# SH30F2xx register map
Vendor: Sino Wealth Electronic Ltd.; Series: SH30Fxxx; File version: 1.0
CPU: CM0+ r0p1, little endian, no MPU, no FPU, 2 interrupt priority bits
Registers are 32-bit, read-write, reset 0x0 unless marked. A register's access mark holds for its fields unless they carry their own. Offsets are from the block's base; [hi:lo] are bit positions; {n}, {i} and the like mark numbered series; 'fields as' and 'values as' point back to an identical list.

## SYSCFG
Base 0x40040800
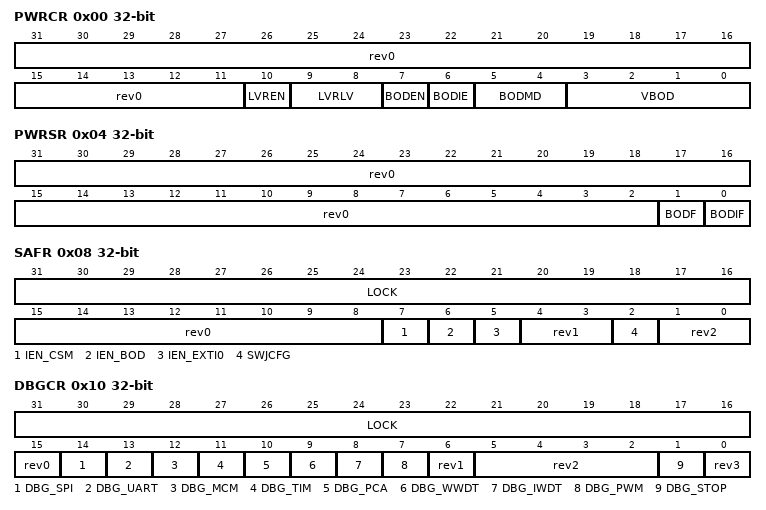
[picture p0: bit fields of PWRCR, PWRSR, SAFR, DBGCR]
0x00 PWRCR
  [31:11] rev0, [10] LVREN, [9:8] LVRLV, [7] BODEN, [6] BODIE, [5:4] BODMD, [3:0] VBOD
0x04 PWRSR
  [31:2] rev0, [1] BODF ro, [0] BODIF
0x08 SAFR
  [31:16] LOCK, [15:8] rev0, [7] IEN_CSM, [6] IEN_BOD, [5] IEN_EXTI0, [4:3] rev1, [2] SWJCFG, [1:0] rev2
0x10 DBGCR
  [31:16] LOCK, [15] rev0, [14] DBG_SPI, [13] DBG_UART, [12] DBG_MCM, [11] DBG_TIM, [10] DBG_PCA, [9] DBG_WWDT, [8] DBG_IWDT, [7] DBG_PWM, [6] rev1, [5:2] rev2, [1] DBG_STOP, [0] rev3
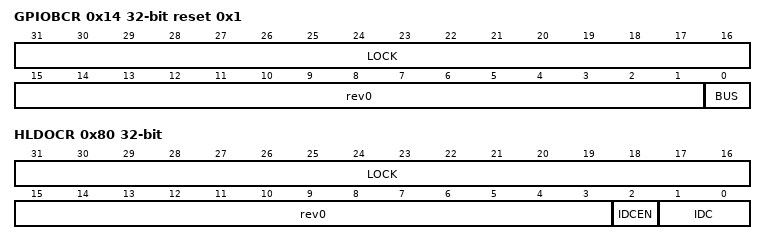
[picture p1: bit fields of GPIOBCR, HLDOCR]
0x14 GPIOBCR reset 0x1
  [31:16] LOCK, [15:1] rev0, [0] BUS
0x80 HLDOCR
  [31:16] LOCK, [15:3] rev0, [2] IDCEN, [1:0] IDC

## RCC
Base 0x40040C00
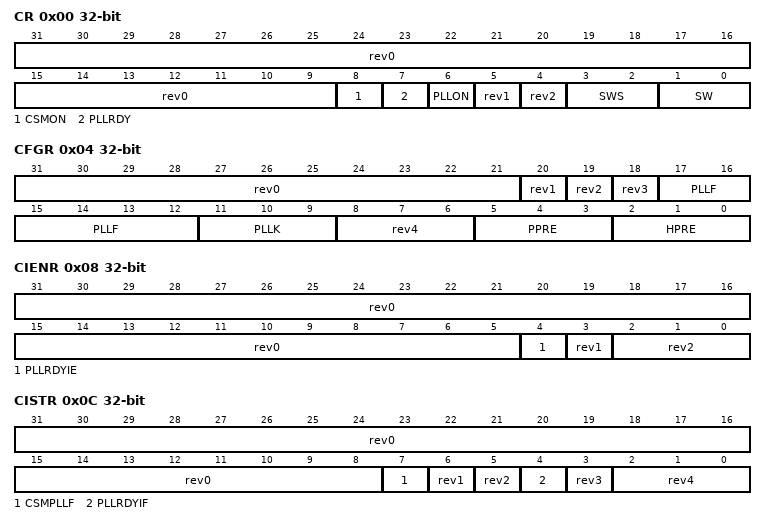
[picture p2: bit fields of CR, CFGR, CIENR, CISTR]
0x00 CR
  [31:9] rev0, [8] CSMON, [7] PLLRDY ro, [6] PLLON, [5] rev1 ro, [4] rev2, [3:2] SWS ro, [1:0] SW
0x04 CFGR
  [31:21] rev0, [20] rev1, [19] rev2, [18] rev3, [17:12] PLLF, [11:9] PLLK, [8:6] rev4, [5:3] PPRE, [2:0] HPRE
0x08 CIENR
  [31:5] rev0, [4] PLLRDYIE, [3] rev1, [2:0] rev2
0x0C CISTR ro
  [31:8] rev0 rw, [7] CSMPLLF, [6] rev1, [5] rev2 rw, [4] PLLRDYIF, [3] rev3, [2:0] rev4 rw
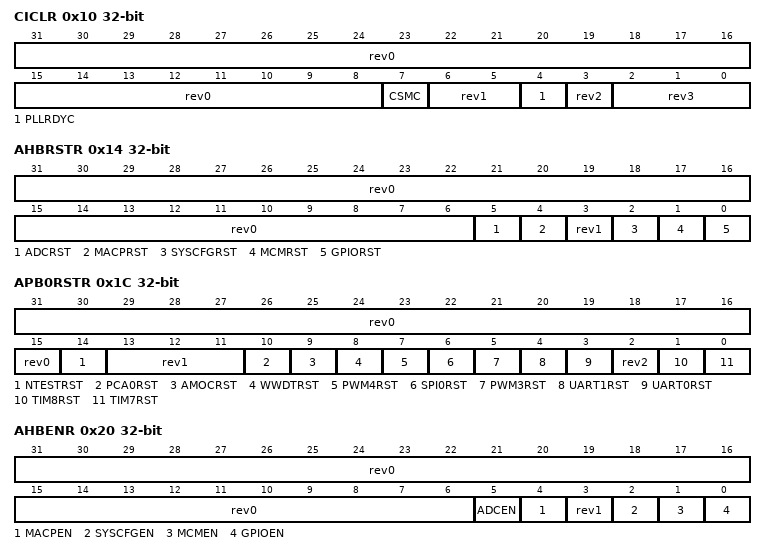
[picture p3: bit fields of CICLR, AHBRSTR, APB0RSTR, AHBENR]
0x10 CICLR
  [31:8] rev0, [7] CSMC, [6:5] rev1, [4] PLLRDYC, [3] rev2, [2:0] rev3
0x14 AHBRSTR
  [31:6] rev0, [5] ADCRST, [4] MACPRST, [3] rev1, [2] SYSCFGRST, [1] MCMRST, [0] GPIORST
0x1C APB0RSTR
  [31:15] rev0, [14] NTESTRST, [13:11] rev1, [10] PCA0RST, [9] AMOCRST, [8] WWDTRST, [7] PWM4RST, [6] SPI0RST, [5] PWM3RST, [4] UART1RST, [3] UART0RST, [2] rev2, [1] TIM8RST, [0] TIM7RST
0x20 AHBENR
  [31:6] rev0, [5] ADCEN, [4] MACPEN, [3] rev1, [2] SYSCFGEN, [1] MCMEN, [0] GPIOEN
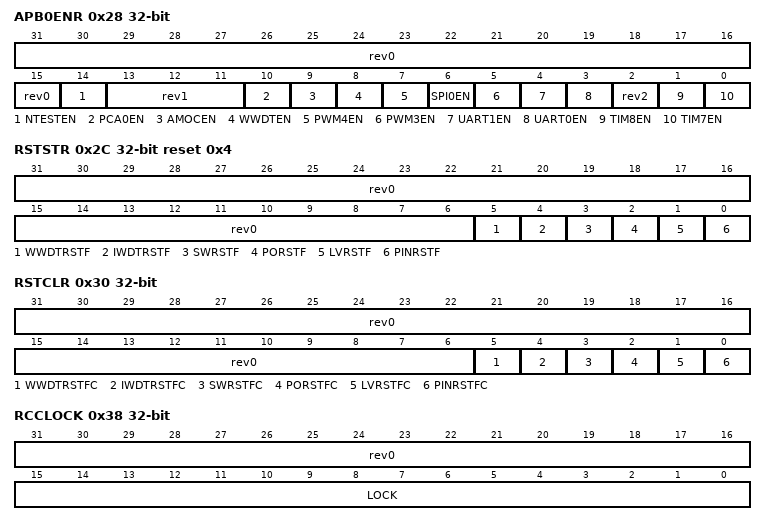
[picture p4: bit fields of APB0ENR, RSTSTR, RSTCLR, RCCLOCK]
0x28 APB0ENR
  [31:15] rev0, [14] NTESTEN, [13:11] rev1, [10] PCA0EN, [9] AMOCEN, [8] WWDTEN, [7] PWM4EN, [6] SPI0EN, [5] PWM3EN, [4] UART1EN, [3] UART0EN, [2] rev2, [1] TIM8EN, [0] TIM7EN
0x2C RSTSTR ro reset 0x4
  [31:6] rev0 rw, [5] WWDTRSTF, [4] IWDTRSTF, [3] SWRSTF, [2] PORSTF, [1] LVRSTF, [0] PINRSTF
0x30 RSTCLR
  [31:6] rev0, [5] WWDTRSTFC, [4] IWDTRSTFC, [3] SWRSTFC, [2] PORSTFC, [1] LVRSTFC, [0] PINRSTFC
0x38 RCCLOCK
  [31:16] rev0, [15:0] LOCK

## FLASH
Base 0x40041000
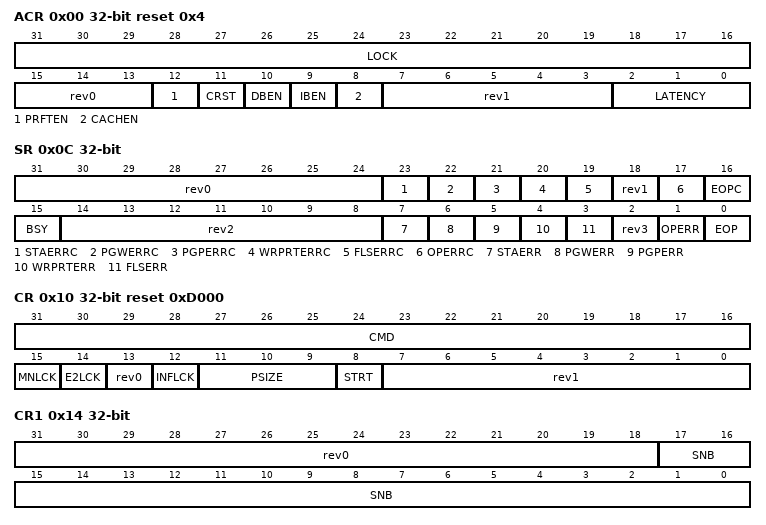
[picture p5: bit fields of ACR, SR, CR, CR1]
0x00 ACR reset 0x4
  [31:16] LOCK, [15:13] rev0, [12] PRFTEN, [11] CRST, [10] DBEN, [9] IBEN, [8] CACHEN, [7:3] rev1, [2:0] LATENCY
0x04 MKYR wo
0x08 E2KYR wo
0x0C SR
  [31:24] rev0, [23] STAERRC, [22] PGWERRC, [21] PGPERRC, [20] WRPRTERRC, [19] FLSERRC, [18] rev1, [17] OPERRC, [16] EOPC, [15] BSY ro, [14:8] rev2, [7] STAERR ro, [6] PGWERR ro, [5] PGPERR ro, [4] WRPRTERR ro, [3] FLSERR ro, [2] rev3, [1] OPERR ro, [0] EOP ro
0x10 CR reset 0xD000
  [31:16] CMD, [15] MNLCK, [14] E2LCK, [13] rev0, [12] INFLCK, [11:9] PSIZE, [8] STRT, [7:0] rev1
0x14 CR1
  [31:18] rev0, [17:0] SNB
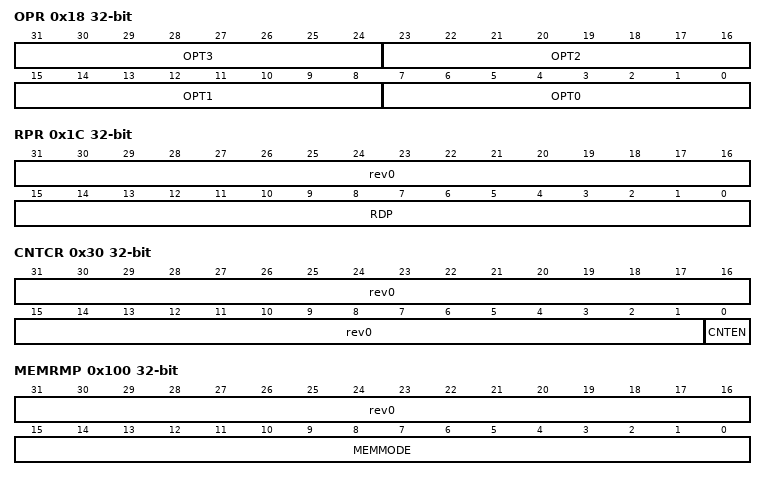
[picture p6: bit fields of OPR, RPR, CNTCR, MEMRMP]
0x18 OPR ro
  [8n+7:8n] OPT{n} (n=0..3)
0x1C RPR ro
  [31:16] rev0 rw, [15:0] RDP
0x20 WRPR ro
0x24 WRPR1 ro
0x28 CNTR
0x2C UPCNTR
0x30 CNTCR
  [31:1] rev0, [0] CNTEN
0x34 IKYR wo
{0x38+4i} DATA{i} (i=0..2)
0x100 MEMRMP
  [31:16] rev0, [15:0] MEMMODE
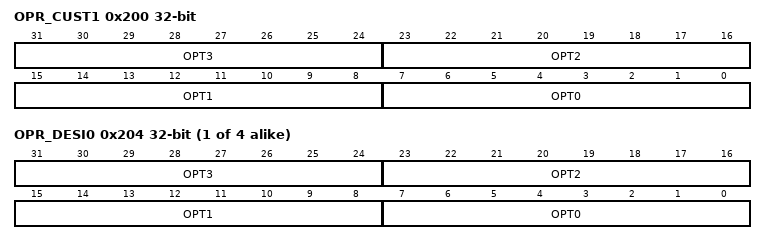
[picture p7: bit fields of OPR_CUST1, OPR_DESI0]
0x200 OPR_CUST1 ro
  [8n+7:8n] OPT{n} (n=0..3)
{0x204+4i} OPR_DESI{i} ro (i=0..3)
  [8n+7:8n] OPT{n} (n=0..3)

## MACP
Base 0x40041400
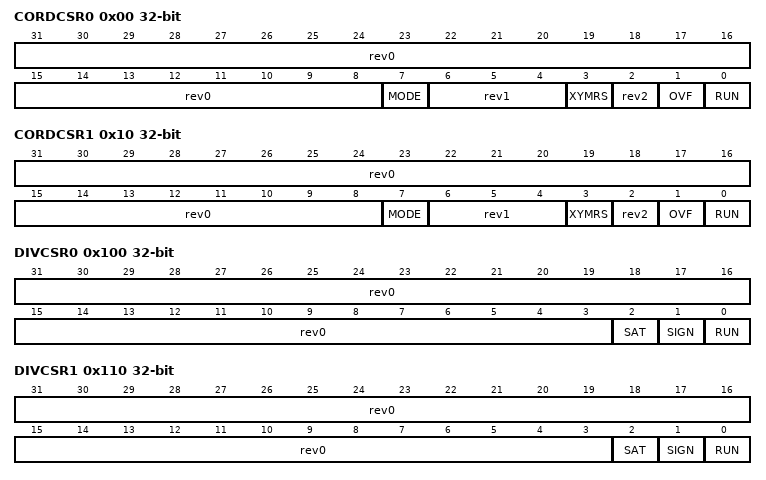
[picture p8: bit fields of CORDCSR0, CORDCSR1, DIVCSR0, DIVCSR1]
0x00 CORDCSR0
  [31:8] rev0, [7] MODE, [6:4] rev1, [3] XYMRS, [2] rev2, [1] OVF ro, [0] RUN
0x04 OPRDX0
0x08 OPRDY0
0x0C OPRDZ0
0x10 CORDCSR1
  fields as CORDCSR0
0x14 OPRDX1
0x18 OPRDY1
0x1C OPRDZ1
0x100 DIVCSR0
  [31:3] rev0, [2] SAT, [1] SIGN, [0] RUN
0x104 DIVDND0
0x108 DIVSOR0
0x10C DIVRLT0 ro
0x110 DIVCSR1
  [31:3] rev0, [2] SAT, [1] SIGN, [0] RUN
0x114 DIVDND1
0x118 DIVSOR1
0x11C DIVRLT1 ro

## ADC
Base 0x40041800
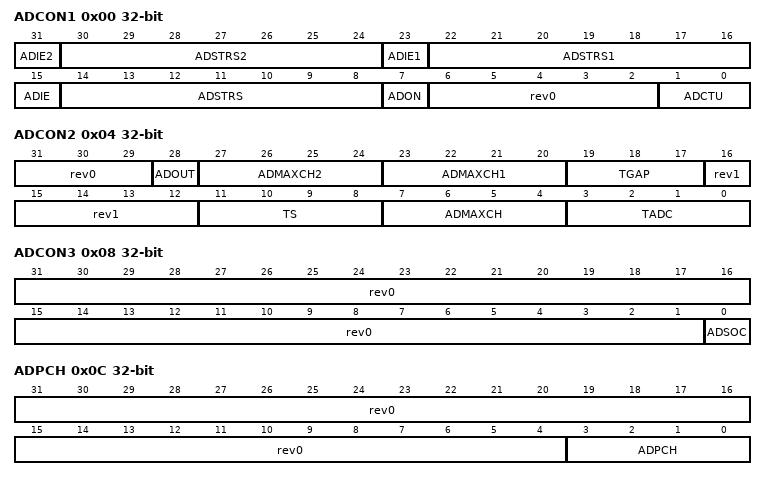
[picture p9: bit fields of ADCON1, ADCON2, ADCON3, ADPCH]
0x00 ADCON1
  [31] ADIE2, [30:24] ADSTRS2, [23] ADIE1, [22:16] ADSTRS1, [15] ADIE, [14:8] ADSTRS, [7] ADON, [6:2] rev0, [1:0] ADCTU
0x04 ADCON2
  [31:29] rev0, [28] ADOUT, [27:24] ADMAXCH2, [23:20] ADMAXCH1, [19:17] TGAP, [16:12] rev1, [11:8] TS, [7:4] ADMAXCH, [3:0] TADC
0x08 ADCON3
  [31:1] rev0, [0] ADSOC
0x0C ADPCH ro
  [31:4] rev0 rw, [3:0] ADPCH
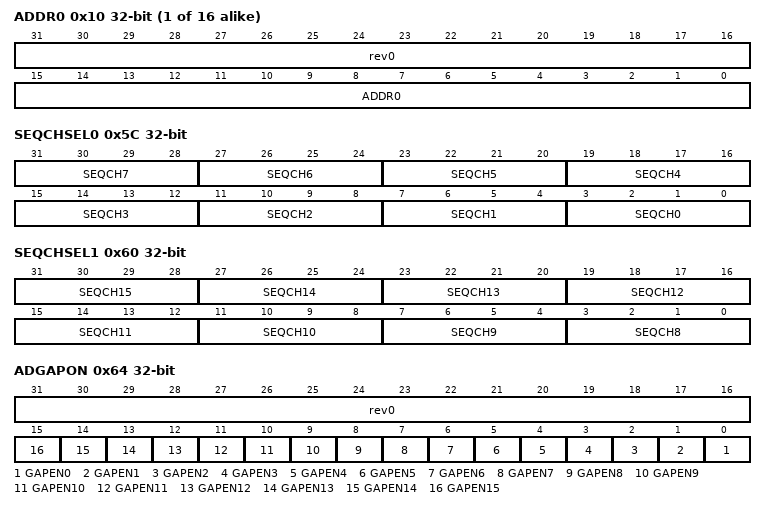
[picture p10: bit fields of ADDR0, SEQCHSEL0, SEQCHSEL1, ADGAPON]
{0x10+4i} ADDR{i} ro (i=0..15)
  [31:16] rev0 rw, [15:0] ADDR{i}
0x5C SEQCHSEL0
  [4n+3:4n] SEQCH{n} (n=0..7)
0x60 SEQCHSEL1
  [4n-29:4n-32] SEQCH{n} (n=8..15)
0x64 ADGAPON
  [31:16] rev0, [n] GAPEN{n} (n=0..15)
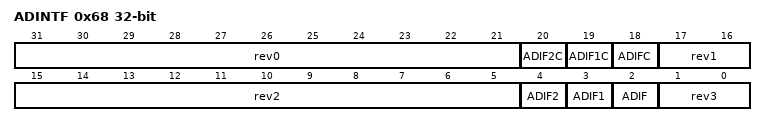
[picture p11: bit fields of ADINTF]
0x68 ADINTF
  [31:21] rev0, [20] ADIF2C, [19] ADIF1C, [18] ADIFC, [17:16] rev1, [15:5] rev2, [4] ADIF2 ro, [3] ADIF1 ro, [2] ADIF ro, [1:0] rev3
